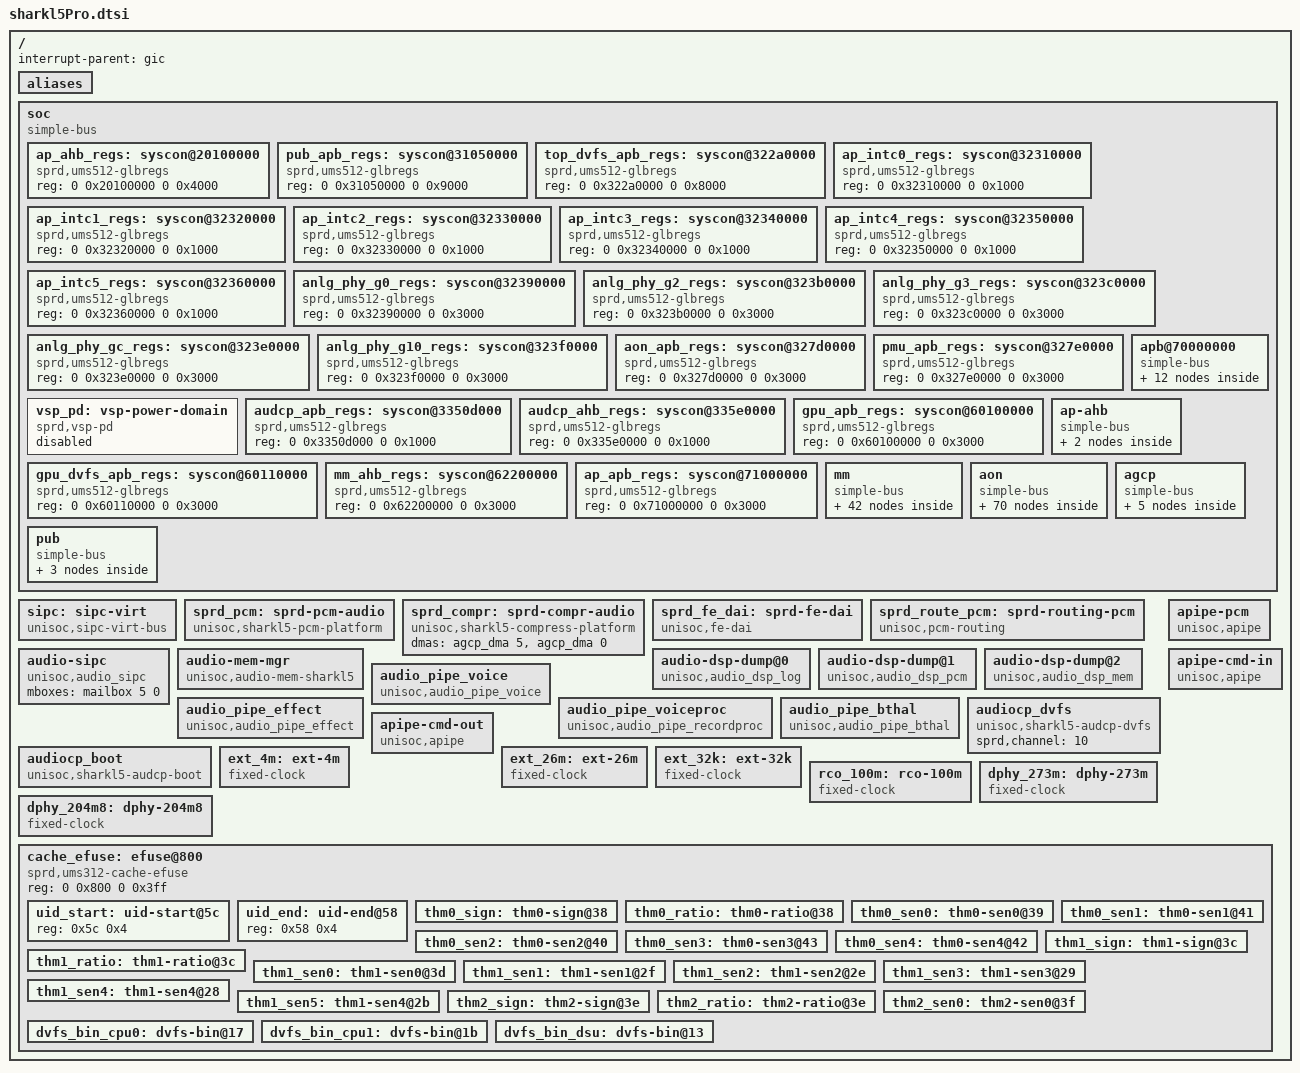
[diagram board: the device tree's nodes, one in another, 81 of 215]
// SPDX-License-Identifier: GPL-2.0-only
/*
 * Unisoc Sharkl5Pro platform DTS file
 *
 * Copyright (C) 2020, Unisoc Inc.
 */

#include <dt-bindings/soc/sprd,sharkl5pro-regs.h>
#include <dt-bindings/soc/sprd,sharkl5pro-mask.h>
#include <dt-bindings/clock/sprd,ums512-clk.h>
#include <dt-bindings/debug/busmonitor/busmonitor.h>
#include <dt-bindings/debug/dmc_mpu/sharkl5pro_dmc_mpu.h>
#include "ums512-qos.dtsi"

/ {
	interrupt-parent = <&gic>;
	#address-cells = <2>;
	#size-cells = <2>;

	aliases {
		i2c0 = &i2c0;
		i2c1 = &i2c1;
		i2c2 = &i2c2;
		i2c3 = &i2c3;
		i2c4 = &i2c4;
		i2c5 = &aon_i2c0;
		spi0 = &spi0;
		spi1 = &spi1;
		spi2 = &spi2;
		spi3 = &spi3;
		spi4 = &adi_bus;
	};

	soc: soc {
		compatible = "simple-bus";
		#address-cells = <2>;
		#size-cells = <2>;
		ranges;

		ap_ahb_regs: syscon@20100000 {
			compatible = "sprd,ums512-glbregs", "syscon";
			reg = <0 0x20100000 0 0x4000>;
		};

		pub_apb_regs: syscon@31050000 {
			compatible = "sprd,ums512-glbregs", "syscon";
			reg = <0 0x31050000 0 0x9000>;
		};

		top_dvfs_apb_regs: syscon@322a0000 {
			compatible = "sprd,ums512-glbregs", "syscon";
			reg = <0 0x322a0000 0 0x8000>;
		};

		ap_intc0_regs: syscon@32310000 {
			compatible = "sprd,ums512-glbregs", "syscon";
			reg = <0 0x32310000 0 0x1000>;
		};

		ap_intc1_regs: syscon@32320000 {
			compatible = "sprd,ums512-glbregs", "syscon";
			reg = <0 0x32320000 0 0x1000>;
		};

		ap_intc2_regs: syscon@32330000 {
			compatible = "sprd,ums512-glbregs", "syscon";
			reg = <0 0x32330000 0 0x1000>;
		};

		ap_intc3_regs: syscon@32340000 {
			compatible = "sprd,ums512-glbregs", "syscon";
			reg = <0 0x32340000 0 0x1000>;
		};

		ap_intc4_regs: syscon@32350000 {
			compatible = "sprd,ums512-glbregs", "syscon";
			reg = <0 0x32350000 0 0x1000>;
		};

		ap_intc5_regs: syscon@32360000 {
			compatible = "sprd,ums512-glbregs", "syscon";
			reg = <0 0x32360000 0 0x1000>;
		};

		anlg_phy_g0_regs: syscon@32390000 {
			compatible = "sprd,ums512-glbregs", "syscon";
			reg = <0 0x32390000 0 0x3000>;
		};

		anlg_phy_g2_regs: syscon@323b0000 {
			compatible = "sprd,ums512-glbregs", "syscon";
			reg = <0 0x323b0000 0 0x3000>;
		};

		anlg_phy_g3_regs: syscon@323c0000 {
			compatible = "sprd,ums512-glbregs", "syscon";
			reg = <0 0x323c0000 0 0x3000>;
		};

		anlg_phy_gc_regs: syscon@323e0000 {
			compatible = "sprd,ums512-glbregs", "syscon";
			reg = <0 0x323e0000 0 0x3000>;
		};

		anlg_phy_g10_regs: syscon@323f0000 {
			compatible = "sprd,ums512-glbregs", "syscon";
			reg = <0 0x323f0000 0 0x3000>;
		};

		aon_apb_regs: syscon@327d0000 {
			compatible = "sprd,ums512-glbregs", "syscon";
			reg = <0 0x327d0000 0 0x3000>;
		};

		pmu_apb_regs: syscon@327e0000 {
			compatible = "sprd,ums512-glbregs", "syscon";
			reg = <0 0x327e0000 0 0x3000>;
		};

		vsp_pd: vsp-power-domain {
			compatible = "sprd,vsp-pd";
			pmu-vsp-force-shutdown-syscon = <&pmu_apb_regs
				REG_PMU_APB_RF_PD_AP_VSP_CFG
				MASK_PMU_APB_RF_PD_AP_VSP_FORCE_SHUTDOWN>;
			pmu-vsp-auto-shutdown-syscon = <&pmu_apb_regs
				REG_PMU_APB_RF_PD_AP_VSP_CFG
				MASK_PMU_APB_RF_PD_AP_VSP_AUTO_SHUTDOWN_EN>;
			pmu-pwr-status-syscon = <&pmu_apb_regs
				REG_PMU_APB_RF_PWR_STATUS0_DBG
				MASK_PMU_APB_RF_PD_AP_VSP_STATE>;
			#power-domain-cells = <0>;
			status = "disabled";
		};

		audcp_apb_regs: syscon@3350d000 {
			compatible = "sprd,ums512-glbregs", "syscon";
			reg = <0 0x3350d000 0 0x1000>;
		};

		audcp_ahb_regs: syscon@335e0000 {
			compatible = "sprd,ums512-glbregs", "syscon";
			reg = <0 0x335e0000 0 0x1000>;
		};

		gpu_apb_regs: syscon@60100000 {
			compatible = "sprd,ums512-glbregs", "syscon";
			reg = <0 0x60100000 0 0x3000>;
		};

		gpu_dvfs_apb_regs: syscon@60110000 {
			compatible = "sprd,ums512-glbregs", "syscon";
			reg = <0 0x60110000 0 0x3000>;
		};

		mm_ahb_regs: syscon@62200000 {
			compatible = "sprd,ums512-glbregs", "syscon";
			reg = <0 0x62200000 0 0x3000>;
		};

		apb@70000000 {
			compatible = "simple-bus";
			#address-cells = <1>;
			#size-cells = <1>;
			ranges = <0 0x0 0x70000000 0x10000000>;

			uart0: serial@0 {
				compatible = "sprd,ums512-uart",
					     "sprd,sc9836-uart";
				reg = <0x0 0x100>;
				interrupts = <GIC_SPI 2 IRQ_TYPE_LEVEL_HIGH>;
				source-base = <0x20200028>;
				clock-frequency = <0>;
				uart-eb-syscon = <&ap_apb_regs
						REG_AP_APB_RF_APB_EB
						MASK_AP_APB_RF_UART0_EB>;
				clocks = <&ext_26m>;
				status = "disabled";
			};

			uart1: serial@100000 {
				compatible = "sprd,ums512-uart",
					     "sprd,sc9836-uart";
				reg = <0x100000 0x100>;
				interrupts = <GIC_SPI 3 IRQ_TYPE_LEVEL_HIGH>;
				source-base = <0x2020002c>;
				clock-frequency = <0>;
				uart-eb-syscon = <&ap_apb_regs
						REG_AP_APB_RF_APB_EB
						MASK_AP_APB_RF_UART1_EB>;
				clocks = <&ext_26m>;
				status = "disabled";
			};

			i2c0: i2c@300000 {
				compatible = "sprd,ums512-i2c", "sprd,sc9860-i2c";
				reg = <0x300000 0x100>;
				interrupts = <GIC_SPI 11 IRQ_TYPE_LEVEL_HIGH>;
				clock-frequency = <400000>;
				#address-cells = <1>;
				#size-cells = <0>;
				status = "disabled";
			};

			i2c1: i2c@400000 {
				compatible = "sprd,ums512-i2c", "sprd,sc9860-i2c";
				reg = <0x400000 0x100>;
				interrupts = <GIC_SPI 12 IRQ_TYPE_LEVEL_HIGH>;
				clock-frequency = <400000>;
				#address-cells = <1>;
				#size-cells = <0>;
				status = "disabled";
			};

			i2c2: i2c@500000 {
				compatible = "sprd,ums512-i2c", "sprd,sc9860-i2c";
				reg = <0x500000 0x100>;
				interrupts = <GIC_SPI 13 IRQ_TYPE_LEVEL_HIGH>;
				clock-frequency = <400000>;
				#address-cells = <1>;
				#size-cells = <0>;
				status = "disabled";
			};

			i2c3: i2c@600000 {
				compatible = "sprd,ums512-i2c", "sprd,sc9860-i2c";
				reg = <0x600000 0x100>;
				interrupts = <GIC_SPI 14 IRQ_TYPE_LEVEL_HIGH>;
				clock-frequency = <400000>;
				#address-cells = <1>;
				#size-cells = <0>;
				status = "disabled";
			};

			i2c4: i2c@700000 {
				compatible = "sprd,ums512-i2c", "sprd,sc9860-i2c";
				reg = <0x700000 0x100>;
				interrupts = <GIC_SPI 15 IRQ_TYPE_LEVEL_HIGH>;
				clock-frequency = <400000>;
				#address-cells = <1>;
				#size-cells = <0>;
				status = "disabled";
			};

			spi0: spi@800000{
				compatible = "sprd,ums512-spi",
					     "sprd,sc9860-spi";
				reg = <0x800000 0x1000>;
				interrupts = <GIC_SPI 5 IRQ_TYPE_LEVEL_HIGH>;
				#address-cells = <1>;
				#size-cells = <0>;
				status = "disabled";
			};

			spi1: spi@900000{
				compatible = "sprd,ums512-spi",
					     "sprd,sc9860-spi";
				reg = <0x900000 0x1000>;
				interrupts = <GIC_SPI 6 IRQ_TYPE_LEVEL_HIGH>;
				#address-cells = <1>;
				#size-cells = <0>;
				status = "disabled";
			};

			spi2: spi@a00000{
				compatible = "sprd,ums512-spi",
					     "sprd,sc9860-spi";
				reg = <0xa00000 0x1000>;
				interrupts = <GIC_SPI 7 IRQ_TYPE_LEVEL_HIGH>;
				#address-cells = <1>;
				#size-cells = <0>;
				status = "disabled";
			};

			spi3: spi@b00000{
				compatible = "sprd,ums512-spi",
					     "sprd,sc9860-spi";
				reg = <0xb00000 0x1000>;
				interrupts = <GIC_SPI 8 IRQ_TYPE_LEVEL_HIGH>;
				#address-cells = <1>;
				#size-cells = <0>;
				status = "disabled";
			};

			apsys_dvfs: apsys-dvfs@1700000 {
				compatible = "sprd,hwdvfs-apsys-sharkl5pro";
				reg = <0x1700000 0x15c>;

				sprd,ap-dvfs-up-window = <0x40>;
				sprd,ap-dvfs-down-window = <0x80>;
			};
		};

		ap_apb_regs: syscon@71000000 {
			compatible = "sprd,ums512-glbregs", "syscon";
			reg = <0 0x71000000 0 0x3000>;
		};

		ap-ahb {
			compatible = "simple-bus";
			#address-cells = <2>;
			#size-cells = <2>;
			ranges;

			ap_dma: dma-controller@20000000 {
				compatible = "sprd,sharkl5pro-dma", "sprd,sc9860-dma";
				reg = <0 0x20000000 0 0x4000>;
				interrupts = <GIC_SPI 24 IRQ_TYPE_LEVEL_HIGH>;
				#dma-cells = <1>;
				#dma-channels = <28>;
				clock-names = "enable";
				clocks = <&apahb_gate CLK_DMA_PUB_EB>;
			};

			vdsp: vdsp@20900000 {
				compatible = "sprd,sharkl5pro-vdsp";
				/* IPI */
				reg = <0x0 0x20900000 0x0 0x10000>;
				sprd,syscon-ap-ahb = <&ap_ahb_regs>;
				sprd,syscon-pmu = <&pmu_apb_regs>;
				clock-names = "vdsp_clk_set","vdsp_clk_512";
				clocks = <&ap_clk CLK_VDSP>,
					     <&pll2  CLK_TWPLL_512M>;
				iommu_names = "unisoc,iommuvau-epp-l5p",
							"unisoc,iommuvau-edp-l5p",
							"unisoc,iommuvau-idma-l5p",
							"unisoc,iommuvau-vdma-l5p";
				queue-priority = <7 8 9>;
				/* offset, bit#, IRQ# */
				device-irq = <0 4 1>;
				device-irq-host-offset = <0>;
				device-irq-mode = <1>;
				/* offset, bit# */
				host-irq = <0x8 0>;
				host-irq-mode = <1>;
				interrupts = <GIC_SPI 169 IRQ_TYPE_LEVEL_HIGH>;
				firmware-name = "vdsp_firmware.bin";
				/* vdsp-qos = <&vdsp_qos>; */
				status = "disabled";
			};
		};

		mm {
			compatible = "simple-bus";
			#address-cells = <2>;
			#size-cells = <2>;
			ranges;

			gpu: gpu@60000000 {
				compatible = "sprd,mali-gondul";
				reg = <0x0 0x60000000 0x0 0x100000>;
				gpu-supply = <&vddgpu>;
				system-coherency = <31>;
				top_force_shutdown = <&pmu_apb_regs
					REG_PMU_APB_RF_PD_GPU_TOP_CFG0
					MASK_PMU_APB_RF_PD_GPU_TOP_FORCE_SHUTDOWN>;
				mem_repaired_flag = <&aon_apb_regs
					REG_AON_APB_RF_BOND_OPT0
					MASK_AON_APB_RF_BOND_OPTION0>;
				gpu_qos_sel = <&gpu_apb_regs
					REG_GPU_APB_RF_GPU_NIC400_QOS
					MASK_GPU_APB_RF_GPU_QOS_SEL>;
				gpu_qos = <&gpu_apb_regs
					REG_GPU_APB_RF_GPU_NIC400_QOS
					(MASK_GPU_APB_RF_AWQOS_THRESHOLD_GPU |
					MASK_GPU_APB_RF_ARQOS_THRESHOLD_GPU |
					MASK_GPU_APB_RF_AWQOS_GPU |
					MASK_GPU_APB_RF_ARQOS_GPU)>;
				dvfs_index_cfg = <&gpu_dvfs_apb_regs
					REG_GPU_DVFS_APB_RF_GPU_DVFS_INDEX_CFG
					MASK_GPU_DVFS_APB_RF_GPU_DVFS_INDEX>;
				sw_dvfs_ctrl = <&gpu_dvfs_apb_regs
					REG_GPU_DVFS_APB_RF_GPU_SW_DVFS_CTRL
					(MASK_GPU_DVFS_APB_RF_GPU_DVFS_ACK |
					MASK_GPU_DVFS_APB_RF_GPU_DVFS_VOLTAGE_SW |
					MASK_GPU_DVFS_APB_RF_GPU_DVFS_REQ_SW)>;
				freq_upd_cfg = <&gpu_dvfs_apb_regs
					REG_GPU_DVFS_APB_RF_GPU_FREQ_UPD_TYPE_CFG
					(MASK_GPU_DVFS_APB_RF_GPU_CORE_FREQ_UPD_HDSK_EN |
					 MASK_GPU_DVFS_APB_RF_GPU_CORE_FREQ_UPD_DELAY_EN)>;
				core_index0_map = <&gpu_dvfs_apb_regs
					REG_GPU_DVFS_APB_RF_GPU_CORE_INDEX0_MAP
					MASK_GPU_DVFS_APB_RF_GPU_CORE_VOL_INDEX0>;
				core_index1_map = <&gpu_dvfs_apb_regs
					REG_GPU_DVFS_APB_RF_GPU_CORE_INDEX1_MAP
					MASK_GPU_DVFS_APB_RF_GPU_CORE_VOL_INDEX1>;
				core_index2_map = <&gpu_dvfs_apb_regs
					REG_GPU_DVFS_APB_RF_GPU_CORE_INDEX2_MAP
					MASK_GPU_DVFS_APB_RF_GPU_CORE_VOL_INDEX2>;
				core_index3_map = <&gpu_dvfs_apb_regs
					REG_GPU_DVFS_APB_RF_GPU_CORE_INDEX3_MAP
					MASK_GPU_DVFS_APB_RF_GPU_CORE_VOL_INDEX3>;
				core_index4_map = <&gpu_dvfs_apb_regs
					REG_GPU_DVFS_APB_RF_GPU_CORE_INDEX4_MAP
					MASK_GPU_DVFS_APB_RF_GPU_CORE_VOL_INDEX4>;
				core_index5_map = <&gpu_dvfs_apb_regs
					REG_GPU_DVFS_APB_RF_GPU_CORE_INDEX5_MAP
					MASK_GPU_DVFS_APB_RF_GPU_CORE_VOL_INDEX5>;
				core_index6_map = <&gpu_dvfs_apb_regs
					REG_GPU_DVFS_APB_RF_GPU_CORE_INDEX6_MAP
					MASK_GPU_DVFS_APB_RF_GPU_CORE_VOL_INDEX6>;
				core_index7_map = <&gpu_dvfs_apb_regs
					REG_GPU_DVFS_APB_RF_GPU_CORE_INDEX7_MAP
					MASK_GPU_DVFS_APB_RF_GPU_CORE_VOL_INDEX7>;

				interrupts = <GIC_SPI 60 IRQ_TYPE_LEVEL_HIGH>,
					<GIC_SPI 60 IRQ_TYPE_LEVEL_HIGH>,
					<GIC_SPI 60 IRQ_TYPE_LEVEL_HIGH>;
				interrupt-names = "JOB",
					"MMU",
					"GPU";

				/*nvmem-cells = <&gpu_bin>;
				nvmem-cell-names = "gpu_bin";*/

				operating-points = <
					/* kHz    uV */
					384000    700000
					512000    750000
					614400    750000
					768000    800000
					850000    800000
					>;

				sprd,dvfs-lists = <
					/* kHz   uV      idx div */
					384000  700000    4    1
					512000  750000    5    1
					614400  750000    6    1
					768000  800000    7    1
					850000  800000    8    1
					>;

				sprd,dvfs-default = <0>;
				/*sprd,qos = <&gpu_qos>;*/
				sprd,dvfs-scene-extreme = <3>;
				sprd,dvfs-scene-high = <2>;
				sprd,dvfs-scene-medium = <1>;
				sprd,dvfs-scene-low = <0>;
				sprd,dvfs-range-max = <4>;
				sprd,dvfs-range-min = <0>;
			};

			mm_domain: power-domain@327e0024 {
				compatible = "sprd,sharkl5pro-camsys-domain";
				force-shutdown = <&pmu_apb_regs
					REG_PMU_APB_RF_PD_MM_TOP_CFG
					MASK_PMU_APB_RF_PD_MM_TOP_FORCE_SHUTDOWN>;
				shutdown-en = <&pmu_apb_regs
					REG_PMU_APB_RF_PD_MM_TOP_CFG
					MASK_PMU_APB_RF_PD_MM_TOP_AUTO_SHUTDOWN_EN>;
				power-state = <&pmu_apb_regs
					REG_PMU_APB_RF_PWR_STATUS3_DBG
					MASK_PMU_APB_RF_PD_MM_TOP_STATE>;
				qos-ar = <&mm_ahb_regs
					REG_MM_AHB_RF_MM_QOS
					MASK_MM_AHB_RF_AR_QOS_THRESHOLD_MM>;
				qos-aw = <&mm_ahb_regs
					REG_MM_AHB_RF_MM_QOS
					MASK_MM_AHB_RF_AW_QOS_THRESHOLD_MM>;
				aon-apb-mm-eb = <&aon_apb_regs
					REG_AON_APB_RF_APB_EB0
					MASK_AON_APB_RF_MM_EB>;
				clock-names = "clk_mm_eb",
					"clk_mm_ahb_eb",
					"clk_mm_ahb",
					"clk_mm_ahb_parent",
					"clk_mm_mtx",
					"clk_mm_mtx_parent",
					"clk_isppll";
				clocks = <&aonapb_gate CLK_MM_EB>,
					<&mm_gate CLK_MM_CKG_EB>,
					<&mm_clk CLK_MM_AHB>,
					<&pll2 CLK_TWPLL_153M6>,
					<&mm_clk CLK_MM_MTX>,
					<&pll2 CLK_TWPLL_512M>,
					<&pll2 CLK_ISPPLL_468M>;
				mm_qos_threshold = <&mm_qos_threshold>;
				#power-domain-cells = <0>;
				status = "disabled";
			};

			mipi_csi_phy0: mipi-csi-phy0 {
				compatible = "sprd,mipi-csi-phy";
				sprd,phyid = <0>;
				sprd,phyname = "4lane";
				status = "disabled";
			};

			mipi_csi_phy1: mipi-csi-phy1 {
				compatible = "sprd,mipi-csi-phy";
				sprd,phyid = <1>;
				sprd,phyname = "2p2";
				status = "disabled";
			};

			mipi_csi_phy1_m: mipi-csi-phy1-m {
				compatible = "sprd,mipi-csi-phy";
				sprd,phyid = <3>;
				sprd,phyname = "2p2_m";
				status = "disabled";
			};

			mipi_csi_phy1_s: mipi-csi-phy1-s {
				compatible = "sprd,mipi-csi-phy";
				sprd,phyid = <4>;
				sprd,phyname = "2p2_s";
				status = "disabled";
			};

			mipi_csi_phy2: mipi-csi-phy2 {
				compatible = "sprd,mipi-csi-phy";
				sprd,phyid = <2>;
				sprd,phyname = "2lane";
				status = "disabled";
			};

			csi0: csi00@62300000 {
				compatible = "sprd,csi-controller";
				reg = <0 0x62300000 0 0x1000>;
				interrupts = <GIC_SPI 45 IRQ_TYPE_LEVEL_HIGH>,
					<GIC_SPI 46 IRQ_TYPE_LEVEL_HIGH>,
					<GIC_SPI 47 IRQ_TYPE_LEVEL_HIGH>,
					<GIC_SPI 48 IRQ_TYPE_LEVEL_HIGH>;
				clock-names = "clk_mipi_csi_gate_eb",
					"clk_csi_eb",
					"mipi_csi_src_eb";
				clocks = <&mm_gate CLK_MM_MIPI_CSI0_EB>,
					<&mm_gate CLK_MM_CSI0_EB>,
					<&mm_clk CLK_MIPI_CSI0>;
				sprd,aon-apb-syscon = <&aon_apb_regs>;
				sprd,cam-ahb-syscon = <&mm_ahb_regs>;
				sprd,anlg_phy_g10_controller =
					<&anlg_phy_g10_regs>;
				sprd,csi-id = <0>;
				sprd,dcam-id = <0>;
				sprd,ip-version = <0x200>;
				status = "disabled";
			};

			csi1: csi01@62400000 {
				compatible = "sprd,csi-controller";
				reg = <0 0x62400000 0 0x1000>;
				interrupts = <GIC_SPI 49 IRQ_TYPE_LEVEL_HIGH>,
					<GIC_SPI 50 IRQ_TYPE_LEVEL_HIGH>,
					<GIC_SPI 51 IRQ_TYPE_LEVEL_HIGH>,
					<GIC_SPI 52 IRQ_TYPE_LEVEL_HIGH>;
				clock-names = "clk_mipi_csi_gate_eb",
					"clk_csi_eb",
					"mipi_csi_src_eb";
				clocks = <&mm_gate CLK_MM_MIPI_CSI1_EB>,
					<&mm_gate CLK_MM_CSI1_EB>,
					<&mm_clk CLK_MIPI_CSI1>;
				sprd,aon-apb-syscon = <&aon_apb_regs>;
				sprd,cam-ahb-syscon = <&mm_ahb_regs>;
				sprd,anlg_phy_g10_controller =
					<&anlg_phy_g10_regs>;
				sprd,csi-id = <1>;
				sprd,dcam-id = <1>;
				sprd,ip-version = <0x200>;
				status = "disabled";
			};

			csi2: csi02@62500000 {
				compatible = "sprd,csi-controller";
				reg = <0 0x62500000 0 0x1000>;
				interrupts = <GIC_SPI 53 IRQ_TYPE_LEVEL_HIGH>,
					<GIC_SPI 54 IRQ_TYPE_LEVEL_HIGH>,
					<GIC_SPI 55 IRQ_TYPE_LEVEL_HIGH>,
					<GIC_SPI 56 IRQ_TYPE_LEVEL_HIGH>;
				clock-names = "clk_mipi_csi_gate_eb",
					"clk_csi_eb",
					"mipi_csi_src_eb";
				clocks = <&mm_gate CLK_MM_MIPI_CSI2_EB>,
					<&mm_gate CLK_MM_CSI2_EB>,
					<&mm_clk CLK_MIPI_CSI2>;
				sprd,aon-apb-syscon = <&aon_apb_regs>;
				sprd,cam-ahb-syscon = <&mm_ahb_regs>;
				sprd,anlg_phy_g10_controller =
					<&anlg_phy_g10_regs>;
				sprd,csi-id = <2>;
				sprd,dcam-id = <2>;
				sprd,ip-version = <0x200>;
				status = "disabled";
			};

			isp: isp@62000000 {
				compatible = "sprd,isp";
				reg = <0 0x62000000 0 0x100000>;
				interrupts = <GIC_SPI 43 IRQ_TYPE_LEVEL_HIGH>,
					<GIC_SPI 44 IRQ_TYPE_LEVEL_HIGH>;
				interrupts_name = "ispch0", "ispch1";
				clock-names = "isp_eb",
					"isp_axi_eb", /* no need read, TBC */
					"isp_clk",
					"isp_clk_256m",
					"isp_clk_307m2",
					"isp_clk_384m",
					"isp_clk_468m",
					"isp_clk_512m",
					"isp_clk_parent";
				clocks = <&mm_gate CLK_MM_ISP_EB>,
					<&mm_gate CLK_ISP_AHB_EB>,
					<&mm_clk CLK_ISP>,
					<&pll2 CLK_TWPLL_256M>,
					<&pll2 CLK_TWPLL_307M2>,
					<&pll2 CLK_TWPLL_384M>,
					<&pll2 CLK_ISPPLL_468M>,
					<&pll2 CLK_TWPLL_512M>,
					<&pll2 CLK_TWPLL_512M>;
				reset = <&mm_ahb_regs
					REG_MM_AHB_RF_AHB_RST
					MASK_MM_AHB_RF_ISP_SOFT_RST>;
				isp_ahb_reset = <&mm_ahb_regs
					REG_MM_AHB_RF_AHB_RST
					MASK_MM_AHB_RF_ISP_AHB_SOFT_RST>;
				isp_vau_reset = <&mm_ahb_regs
					REG_MM_AHB_RF_AHB_RST
					MASK_MM_AHB_RF_ISP_VAU_SOFT_RST>;
				isp_enable = <&mm_ahb_regs
					REG_MM_AHB_RF_AHB_EB
					MASK_MM_AHB_RF_ISP_EB>;
				sprd,cam-ahb-syscon = <&mm_ahb_regs>;
				sprd,isp-count = <1>;
				iommus = <&iommu_isp>;
				isp_qos = <&isp_qos>;
				status = "disabled";
			};

			iommu_isp: iommu@62000000 {
				compatible = "unisoc,iommuvaul5p-isp";
				reg = <0x0 0x62000000 0x0 0xff000>,
				      <0x0 0x620ff000 0x0 0x80>;
				iova-base = <0x40000000>;
				iova-size = <0x20000000>;
				reg_name = "mmu_interrupt_reg","mmu_reg";
				status = "disabled";
				#iommu-cells = <0>;
			};

			dcam: dcam@62900000 {
				compatible = "sprd,sharkl5pro-cam";
				reg = <0 0x62900000 0 0x1000>,
					<0 0x62901000 0 0x1000>,
					<0 0x62902000 0 0x1000>,
					<0 0x62903000 0 0x1000>;
				reg-names = "dcam0_reg",
						"dcam1_reg",
						"dcam2_reg",
						"axi_ctrl_reg";
				interrupts = <GIC_SPI 57 IRQ_TYPE_LEVEL_HIGH>,
					<GIC_SPI 58 IRQ_TYPE_LEVEL_HIGH>,
					<GIC_SPI 59 IRQ_TYPE_LEVEL_HIGH>;
				interrupt-names = "dcam0",
							"dcam1",
							"dcam2";
				clock-names = "dcam_eb",
					"dcam_clk",
					"dcam_clk_192m",
					"dcam_clk_256m",
					"dcam_clk_307m2",
					"dcam_clk_384m",
					"dcam_clk_468m",
					"dcam_clk_parent",
					"dcam_axi_eb",
					"dcam_axi_clk",
					"dcam_axi_clk_256m",
					"dcam_axi_clk_307m2",
					"dcam_axi_clk_384m",
					"dcam_axi_clk_468m",
					"dcam_axi_clk_parent";
				clocks = <&mm_gate CLK_MM_DCAM_EB>,
					<&mm_clk CLK_DCAM_IF>,
					<&pll2 CLK_TWPLL_192M>,
					<&pll2 CLK_TWPLL_256M>,
					<&pll2 CLK_TWPLL_307M2>,
					<&pll2 CLK_TWPLL_384M>,
					<&pll2 CLK_ISPPLL_468M>,
					<&pll2 CLK_ISPPLL_468M>,
					<&mm_gate CLK_DCAM_AXI_EB>,
					<&mm_clk CLK_DCAM_AXI>,
					<&pll2 CLK_TWPLL_256M>,
					<&pll2 CLK_TWPLL_307M2>,
					<&pll2 CLK_TWPLL_384M>,
					<&pll2 CLK_ISPPLL_468M>,
					<&pll2 CLK_ISPPLL_468M>;
				dcam_all_reset = <&mm_ahb_regs
					REG_MM_AHB_RF_AHB_RST
					MASK_MM_AHB_RF_DCAM_ALL_SOFT_RST>;
				dcam0_reset	= <&mm_ahb_regs
					REG_MM_AHB_RF_AHB_RST
					MASK_MM_AHB_RF_DCAM0_SOFT_RST>;
				dcam1_reset	= <&mm_ahb_regs
					REG_MM_AHB_RF_AHB_RST
					MASK_MM_AHB_RF_DCAM1_SOFT_RST>;
				dcam2_reset	= <&mm_ahb_regs
					REG_MM_AHB_RF_AHB_RST
					MASK_MM_AHB_RF_DCAM2_SOFT_RST>;
				sprd,cam-ahb-syscon = <&mm_ahb_regs>;
				sprd,isp = <&isp>;
				sprd,dcam-count = <3>;
				sprd,dcam-superzoom = <2>;
				sprd,project-id = <3>;
				iommus = <&iommu_dcam>;
				dcam_qos = <&dcam_qos>;
				power-domains = <&mm_domain>;
				status = "disabled";
			};

			iommu_dcam: iommu@62900000 {
				compatible = "unisoc,iommuvaul5p-dcam";
				reg = <0x0 0x62900000 0x0 0xf000>,
				      <0x0 0x6290f000 0x0 0x80>;
				iova-base = <0x40000000>;
				iova-size = <0x40000000>;
				reg_name = "mmu_interrupt_reg","mmu_reg";
				status = "disabled";
				#iommu-cells = <0>;
			};

			cpp: cpp@62800000 {
				compatible = "sprd,cpp";
				reg = <0 0x62800000 0 0x1000>;
				interrupts = <GIC_SPI 41 IRQ_TYPE_LEVEL_HIGH>;
				clock-names = "cpp_eb",
					"cpp_axi_eb", /* no need read, TBC */
					"cpp_clk",
					"cpp_clk_parent";
				clocks = <&mm_gate CLK_MM_CPP_EB>,
					<&mm_gate CLK_MM_ISP_EB>,
					<&mm_clk CLK_CPP>,
					<&pll2 CLK_TWPLL_384M>;
				sprd,cam-ahb-syscon = <&mm_ahb_regs>;
				iommus = <&iommu_cpp>;
				cpp_qos = <&cpp_qos>;
				power-domains = <&mm_domain>;
				status = "disabled";
			};

			iommu_cpp: iommu@62800000 {
				compatible = "unisoc,iommuvaul5p-cpp";
				reg = <0x0 0x62800000 0x0 0x200>,
				      <0x0 0x62800200 0x0 0x80>;
				iova-base = <0x40000000>;
				iova-size = <0x20000000>;
				reg_name = "mmu_interrupt_reg","mmu_reg";
				status = "disabled";
				#iommu-cells = <0>;
			};

			iommu_fd: iommu@62a00000 {
				compatible = "unisoc,iommuvaul5p-fd";
				reg = <0 0x62a00000 0 0x200>,
				      <0 0x62a00110 0 0x80>;
				iova-base = <0x10000000>;
				iova-size = <0x10000000>;
				reg_name = "mmu_interrupt_reg","mmu_reg";
				status = "disabled";
				#iommu-cells = <0>;
			};

			jpg: jpg-codec@62700000 {
				compatible = "sprd,sharkl5pro-jpg";
				reg = <0 0x62700000 0 0xc000>;
				interrupts = <GIC_SPI 42 IRQ_TYPE_LEVEL_HIGH>;
				reset-syscon = <&mm_ahb_regs
					REG_MM_AHB_RF_AHB_RST
					MASK_MM_AHB_RF_JPG_SOFT_RST>;
				aon-apb-eb-syscon = <&aon_apb_regs
					REG_AON_APB_RF_APB_EB0
					MASK_AON_APB_RF_MM_EB>;
				iommus = <&iommu_jpg>;
				power-domains = <&mm_domain>;
				/*sprd,qos = <&jpg_qos>;*/
				status = "disabled";
			};

			iommu_jpg: iommu@62700300 {
				compatible = "unisoc,iommuvaul5p-jpg";
				reg = <0x0 0x62700300 0x0 0x80>,
					<0x0 0x62700300 0x0 0x80>;
				iova-base = <0x60000000>;
				iova-size = <0x10000000>;
				reg_name = "mmu_reg";
				status = "disabled";
				#iommu-cells = <0>;
			};

			dpu: dpu@20300000 {
				compatible = "sprd,sharkl5pro-dpu";
				reg = <0x0 0x20300000 0x0 0x1000>;
				reset-syscon = <&ap_ahb_regs 0x0004 0x2>;
				interrupts = <GIC_SPI 27 IRQ_TYPE_LEVEL_HIGH>;
				status = "disabled";
				iommus = <&iommu_dispc>;
				sprd,qos = <&dpu_qos>;

				dpu_port: port {
					dpu_out: endpoint {
						remote-endpoint = <&dsi_in>;
					};
				};
			};

			gsp_core0: gsp@20300000 {
				compatible = "sprd,gsp-core";
				reg = <0 0x20300000 0 0x2000>;
				core-id = <0>;
				kcfg-num = <16>;
				interrupts = <GIC_SPI 26 IRQ_TYPE_LEVEL_HIGH>;
				iommus = <&iommu_dispc>;
			};

			iommu_dispc: iommu@20300000 {
				compatible = "unisoc,iommuvaul5p-dispc";
				reg = <0x0 0x20300000 0x0 0x800>,
				      <0x0 0x20300800 0x0 0x80>;
				iova-base = <0x30000000>;
				iova-size = <0x10000000>;
				reg_name = "mmu_interrupt_reg","mmu_reg";
				status = "disabled";
				#iommu-cells = <0>;
			};

			dsi: dsi@20400000 {
				compatible = "sprd,sharkl5pro-dsi-host";
				reg = <0x0 0x20400000 0x0 0x1000>;
				reset-syscon = <&ap_ahb_regs 0x0004 0x1>;
				interrupts = <GIC_SPI 30 IRQ_TYPE_LEVEL_HIGH>,
					<GIC_SPI 31 IRQ_TYPE_LEVEL_HIGH>;
				status = "disabled";

				ports {
					#address-cells = <1>;
					#size-cells = <0>;

					port@0 {
						reg = <0>;
						dsi_out: endpoint {
							remote-endpoint = <&dphy_in>;
						};
					};

					port@1 {
						reg = <1>;
						dsi_in: endpoint {
							remote-endpoint = <&dpu_out>;
						};
					};
				};
			};

			dphy: dphy {
				compatible = "sprd,sharkl5pro-dsi-phy";
				#address-cells = <1>;
				#size-cells = <0>;
				reg = <0x0 0x20400000 0x0 0x1000>;
				enable-syscon = <&ap_ahb_regs 0x0040 (0x2 | 0x1)>;
				power-syscon = <&ap_apb_regs 0x035c 0x8>;
				status = "disabled";

				/* output port */
				ports {
					#address-cells = <1>;
					#size-cells = <0>;

					port@0 {
						reg = <0>;
						dphy_out: endpoint {
							remote-endpoint = <&panel_in>;
						};
					};

					/* input port*/
					port@1 {
						reg = <1>;
						dphy_in: endpoint {
							remote-endpoint = <&dsi_out>;
						};
					};
				};
			};

			vsp: video-codec@20500000 {
				compatible = "sprd,sharkl5pro-vsp";
				reg = <0 0x20500000 0 0xc000>;
				interrupts = <GIC_SPI 34 IRQ_TYPE_LEVEL_HIGH>;
				reset-syscon = <&ap_ahb_regs
					REG_AP_AHB_RF_AHB_RST
					(MASK_AP_AHB_RF_VSP_SOFT_RST |
					MASK_AP_AHB_RF_VSP_GLOBAL_SOFT_RST)>;
				vsp-domain-eb-syscon = <&aon_apb_regs
					REG_AON_APB_RF_APB_EB1
					MASK_AON_APB_RF_AP_SYST_EB>;
				iommus = <&iommu_vsp>;
				power-domains = <&vsp_pd>;
				status = "disabled";
			};

			iommu_vsp: iommu@20500000 {
				compatible = "unisoc,iommuvaul5p-vsp";
				reg = <0x0 0x20500000 0x0 0x80>,
				      <0x0 0x20500000 0x0 0x80>;
				iova-base = <0x20000000>;
				iova-size = <0x10000000>;
				reg_name = "mmu_interrupt_reg","mmu_reg";
				status = "disabled";
				#iommu-cells = <0>;
			};

			iommu_vdsp_msti: iommu@20600000 {
				compatible = "unisoc,iommuvau-epp-l5p";
				reg = <0 0x20600000 0 0x400>,
				      <0 0x20600000 0 0x400>;
				reg_name = "mmu_interrupt_reg","mmu_reg";
				iova-base = <0x80000000>;
				iova-size = <0x20000000>;
				status = "disabled";
				#iommu-cells = <0>;
			};

			iommu_vdsp_mstd: iommu@20700000 {
				compatible = "unisoc,iommuvau-edp-l5p";
				reg = <0 0x20700000 0 0x400>,
				      <0 0x20700000 0 0x400>;
				reg_name = "mmu_interrupt_reg","mmu_reg";
				iova-base = <0x80000000>;
				iova-size = <0x20000000>;
				status = "disabled";
				#iommu-cells = <0>;
			};

			iommu_vdsp_idma: iommu@20800000 {
				compatible = "unisoc,iommuvau-idma-l5p";
				reg = <0 0x20800000 0 0x400>,
				      <0 0x20800000 0 0x400>;
				reg_name = "mmu_interrupt_reg","mmu_reg";
				iova-base = <0x80000000>;
				iova-size = <0x20000000>;
				status = "disabled";
				#iommu-cells = <0>;
			};

			iommu_vdsp_vdma: iommu@20a00000 {
				compatible = "unisoc,iommuvau-vdma-l5p";
				reg = <0 0x20a00000 0 0x400>,
				      <0 0x20a00000 0 0x400>;
				reg_name = "mmu_interrupt_reg","mmu_reg";
				iova-base = <0x80000000>;
				iova-size = <0x20000000>;
				status = "disabled";
				#iommu-cells = <0>;
			};
		};

		aon {
			compatible = "simple-bus";
			#address-cells = <2>;
			#size-cells = <2>;
			ranges;

			eic_debounce: gpio@32000000 {
				compatible = "sprd,sharkl5pro-eic-debounce", "sprd,sc9860-eic-debounce";
				reg = <0 0x32020000 0 0x80>,
				      <0 0x32030000 0 0x80>,
				      <0 0x32230000 0 0x80>,
				      <0 0x32270000 0 0x80>;
				gpio-controller;
				#gpio-cells = <2>;
				interrupt-controller;
				#interrupt-cells = <2>;
				interrupts = <GIC_SPI 72 IRQ_TYPE_LEVEL_HIGH>;
			};

			eic_latch: gpio@32000080 {
				compatible = "sprd,sharkl5pro-eic-latch", "sprd,sc9860-eic-latch";
				reg = <0 0x32020080 0 0x20>,
				      <0 0x32030080 0 0x20>,
				      <0 0x32230080 0 0x20>,
				      <0 0x32270080 0 0x20>;
				gpio-controller;
				#gpio-cells = <2>;
				interrupt-controller;
				#interrupt-cells = <2>;
				interrupts = <GIC_SPI 72 IRQ_TYPE_LEVEL_HIGH>;
			};

			eic_async: gpio@320000a0 {
				compatible = "sprd,sharkl5pro-eic-async", "sprd,sc9860-eic-async";
				reg = <0 0x320200a0 0 0x20>,
				      <0 0x320300a0 0 0x20>,
				      <0 0x322300a0 0 0x20>,
				      <0 0x322700a0 0 0x20>;
				gpio-controller;
				#gpio-cells = <2>;
				interrupt-controller;
				#interrupt-cells = <2>;
				interrupts = <GIC_SPI 72 IRQ_TYPE_LEVEL_HIGH>;
			};

			eic_sync: gpio@320000c0 {
				compatible = "sprd,sharkl5pro-eic-sync", "sprd,sc9860-eic-sync";
				reg = <0 0x320200c0 0 0x20>,
				      <0 0x320300c0 0 0x20>,
				      <0 0x322300c0 0 0x20>,
				      <0 0x322700c0 0 0x20>;
				gpio-controller;
				#gpio-cells = <2>;
				interrupt-controller;
				#interrupt-cells = <2>;
				interrupts = <GIC_SPI 72 IRQ_TYPE_LEVEL_HIGH>;
			};

			timer@32040000 {
				compatible = "sprd,sysfrt-timer";
				reg = <0 0x32040000 0 0x10>;
			};

			timer@32050000 {
				compatible = "sprd,sharkl5Pro-timer",
						"sprd,sc9860-timer";
				reg = <0 0x32050000 0 0x20>;
				interrupts = <GIC_SPI 71 IRQ_TYPE_LEVEL_HIGH>;
				clocks = <&ext_32k>;
			};

			timer@32050020 {
				compatible = "sprd,sharkl5Pro-suspend-timer",
						"sprd,sc9860-suspend-timer";
				reg = <0 0x32050020 0 0x20>;
				clocks = <&ext_32k>;
			};

			aon_i2c0: i2c@32060000 {
				compatible = "sprd,sharkl5pro-hw-i2c";
				reg = <0 0x32060000 0 0x1000>;
				interrupts = <GIC_SPI 68 IRQ_TYPE_LEVEL_HIGH>;
				clock-names = "source", "enable", "i2c",
						"clk_hw_i2c";
				clock-frequency = <400000>;
				#address-cells = <1>;
				#size-cells = <0>;
				status = "disabled";
			};

			ap_gpio: gpio@32070000 {
				compatible = "sprd,sharkl5Pro-gpio", "sprd,sc9860-gpio";
				reg = <0 0x32070000 0 0x10000>;
				gpio-controller;
				#gpio-cells = <2>;
				interrupt-controller;
				#interrupt-cells = <2>;
				interrupts = <GIC_SPI 61 IRQ_TYPE_LEVEL_HIGH>;
			};

			mailbox: mailbox@320a0000 {
				compatible = "unisoc,mailbox";
				reg = <0 0x320a0000 0 0x8000>,
				      <0 0x320a8000 0 0x8000>;
				reg-names = "inbox", "outbox";
				sprd,mailbox_clk = <&aon_apb_regs 0x4 0x4>;
				interrupts = <GIC_SPI 82 IRQ_TYPE_LEVEL_HIGH>,
					     <GIC_SPI 83 IRQ_TYPE_LEVEL_HIGH>,
					     <GIC_SPI 84 IRQ_TYPE_LEVEL_HIGH>;
				interrupt-names = "inbox", "outbox", "oob-outbox";
				#mbox-cells = <2>;
			};

			adi_bus: spi@32100000 {
				compatible = "sprd,sharkl5pro-adi";
				reg = <0 0x32100000 0 0x100000>;
				#address-cells = <1>;
				#size-cells = <0>;
			};

			ap_thm0: thermal@32200000 {
				compatible = "sprd,ums512-thermal";
				reg = <0 0x32200000 0 0x10000>;
				#address-cells = <1>;
				#size-cells = <0>;
				clock-names = "enable";
				clocks = <&aonapb_gate CLK_THM0_EB>;
				#thermal-sensor-cells = <1>;
				nvmem-cells = <&thm0_sign>, <&thm0_ratio>;
				nvmem-cell-names = "thm_sign_cal", "thm_ratio_cal";

				sensor@0 {
					reg = <0>;
					nvmem-cells = <&thm0_sen0>;
					nvmem-cell-names = "sen_delta_cal";
				};

				sensor@1 {
					reg = <1>;
					nvmem-cells = <&thm0_sen1>;
					nvmem-cell-names = "sen_delta_cal";
				};

				sensor@2 {
					reg = <2>;
					nvmem-cells = <&thm0_sen2>;
					nvmem-cell-names = "sen_delta_cal";
				};

				sensor@3 {
					reg = <3>;
					nvmem-cells = <&thm0_sen3>;
					nvmem-cell-names = "sen_delta_cal";
				};

				sensor@4 {
					reg = <4>;
					nvmem-cells = <&thm0_sen4>;
					nvmem-cell-names = "sen_delta_cal";
				};
			};

			ap_thm1: thermal@32210000 {
				compatible = "sprd,ums512-thermal";
				reg = <0 0x32210000 0 0x10000>;
				#address-cells = <1>;
				#size-cells = <0>;
				clock-names = "enable";
				clocks = <&aonapb_gate CLK_THM1_EB>;
				#thermal-sensor-cells = <1>;
				nvmem-cells = <&thm1_sign>, <&thm1_ratio>;
				nvmem-cell-names = "thm_sign_cal", "thm_ratio_cal";

				sensor@0 {
					reg = <0>;
					nvmem-cells = <&thm1_sen0>;
					nvmem-cell-names = "sen_delta_cal";
				};

				sensor@1 {
					reg = <1>;
					nvmem-cells = <&thm1_sen1>;
					nvmem-cell-names = "sen_delta_cal";
				};

				sensor@2 {
					reg = <2>;
					nvmem-cells = <&thm1_sen2>;
					nvmem-cell-names = "sen_delta_cal";
				};

				sensor@3 {
					reg = <3>;
					nvmem-cells = <&thm1_sen3>;
					nvmem-cell-names = "sen_delta_cal";
				};

				sensor@4 {
					reg = <4>;
					nvmem-cells = <&thm1_sen4>;
					nvmem-cell-names = "sen_delta_cal";
				};

				sensor@5 {
					reg = <5>;
					nvmem-cells = <&thm1_sen5>;
					nvmem-cell-names = "sen_delta_cal";
				};
			};

			ap_thm2: thermal@32220000 {
				compatible = "sprd,ums512-thermal";
				reg = <0 0x32220000 0 0x10000>;
				#address-cells = <1>;
				#size-cells = <0>;
				clock-names = "enable";
				clocks = <&aonapb_gate CLK_THM2_EB>;
				#thermal-sensor-cells = <1>;
				nvmem-cells = <&thm2_sign>, <&thm2_ratio>;
				nvmem-cell-names = "thm_sign_cal", "thm_ratio_cal";

				sensor@0 {
					reg = <0>;
					nvmem-cells = <&thm2_sen0>;
					nvmem-cell-names = "sen_delta_cal";
				};
			};

			ap_efuse: efuse@32240000 {
				compatible = "sprd,ums312-efuse", "sprd,ums512-efuse";
				reg = <0 0x32240000 0 0x10000>;
				clock-names = "enable";
				hwlocks = <&hwlock 8>;
				clocks = <&aonapb_gate CLK_EFUSE_EB>;
			};

			pwms: pwm@32260000 {
				compatible = "sprd,sharkl5pro-pwm";
				reg = <0 0x32260000 0 0x10000>;
				clock-names = "pwm0", "enable0",
					      "pwm1", "enable1",
					      "pwm2", "enable2";
				clocks = <&aon_clk CLK_PWM0>, <&aonapb_gate CLK_PWM0_EB>,
					 <&aon_clk CLK_PWM1>, <&aonapb_gate CLK_PWM1_EB>,
					 <&aon_clk CLK_PWM2>, <&aonapb_gate CLK_PWM2_EB>;
				assigned-clocks = <&aon_clk CLK_PWM0>,
						  <&aon_clk CLK_PWM1>,
						  <&aon_clk CLK_PWM2>;
				assigned-clock-parents = <&ext_26m>,
							 <&ext_26m>,
							 <&ext_26m>;
				#pwm-cells = <2>;
			      };

			sprd_hardware_cpufreq: hardware-dvfs-platform {
				compatible = "sprd,hardware-cpufreq";
			};

			topdvfs_controller: topdvfsctrl@322a0000 {
				compatible = "sprd,sharkl5pro-topdvfs-dev", "sprd,topdvfs-dev", "syscon";
				sprd,syscon-enable = <&aon_apb_regs>;
				module-enable-cfg = <0x4 7>;
				reg = <0 0x322a0000 0 0x8000>;
				sprd,topdvfs-sysctrl = <&top_dvfs_apb_regs>;
				cpu-dcdc-cells = <&dcdc_cpu0>, <&dcdc_cpu1>;
				device-dcdc-cells = <&dcdc_mm>, <&dcdc_modem>;
				dcdc_cpu0: dcdc-cpu0{
					dcdc-cpu-dvfs-cfg = <&dvfs_dcdc_cpu0_cfg>;
					dvfs-blk-sd-syscon = <&pmu_apb_regs
						REG_PMU_APB_RF_DVFS_BLOCK_SHUTDOWN_CFG
						MASK_PMU_APB_RF_DCDC_CPU0_DVFS_BLOCK_SHUTDOWN_EN>;
				};

				dcdc_cpu1: dcdc-cpu1{
					dcdc-cpu-dvfs-cfg = <&dvfs_dcdc_cpu1_cfg>;
					dvfs-blk-sd-syscon = <&pmu_apb_regs
						REG_PMU_APB_RF_DVFS_BLOCK_SHUTDOWN_CFG
						MASK_PMU_APB_RF_DCDC_CPU1_DVFS_BLOCK_SHUTDOWN_EN>;
				};

				dcdc_mm: dcdc-mm {
					dcdc-dvfs-enable = <0x18 20 1>;
					dcdc-judge-vol-sw = <0x18 1 0x7 2>;
					dcdc-subsys-cells = <&audcp_sys>,
							<&gpu_sys>,
							<&mm_sys>;
					audcp_sys: audcp-sys {
						dcdc-subsys-tune-enable = <0x150 5 0>;
					};
					gpu_sys: gpu-sys {
						dcdc-subsys-tune-enable = <0x150 1 1>;
					};
					mm_sys: mm-sys {
						dcdc-subsys-tune-enable = <0x150 2 0>;
					};
				};

				dcdc_modem: dcdc-modem {
					dcdc-dvfs-enable = <0x3c 20 1>;
					dcdc-judge-vol-sw = <0x3c 1 0x7 2>;
					dcdc-subsys-cells = <&pubcp_sys>,
							<&wtlcp_sys>,
							<&ap_sys>;
					pubcp_sys: pubcp-sys {
						dcdc-subsys-tune-enable = <0x150 4 0>;
					};
					wtlcp_sys: wtlcp-sys {
						dcdc-subsys-tune-enable = <0x150 3 0>;
					};
					ap_sys: ap-sys {
						dcdc-subsys-tune-enable = <0x150 0 1>;
					};
				};
			};

			cpudvfs_dev: cpudvfs-dev@322a8000 {
				compatible = "sprd,sharkl5pro-cpudvfs";
				reg = <0 0x322a8000 0 0x1000>;
				enable-syscon = <&aon_apb_regs REG_AON_APB_RF_APB_EB1 MASK_AON_APB_RF_DVFS_TOP_EB>;
				topdvfs-controller = <&topdvfs_controller>;
				host-cluster-cells = <&lit_core_cluster>,<&big_core_cluster>;
				slave-cluster-cells = <&scu_cluster>, <&periph_cluster>,<&gic_cluster>;
				mpll-cells = <&mpll_0>, <&mpll_1>, <&mpll_2>;
				lit_core_cluster: lit-core-cluster {
					belong-dcdc-cell = <0>;
					/*sel, div, vol, vote_scu, vote_peri, vote_gic, mpllx*/
					lit_core_cluster_tbl = <
						0 0 0 0 0 0 0
						1 1 0 1 1 1 0
						2 1 0 2 1 1 0
						3 0 0 2 1 1 0
						3 0 0 3 1 1 1
						1 0 1 4 1 1 0
						3 0 2 5 4 4 2
						2 0 3 6 4 4 0
						3 0 4 7 4 5 3
						3 0 5 8 4 5 4
						3 0 6 9 5 5 5
						>;
					lit_core_cluster_tbl_ff = <
						0 0 0 0 0 0 0
						1 1 0 1 1 1 0
						2 1 1 2 2 2 0
						3 0 1 3 2 3 0
						3 0 1 4 3 4 1
						1 0 1 5 4 4 0
						3 0 2 6 4 4 2
						2 0 2 7 4 4 0
						3 0 2 8 4 5 3
						3 0 2 9 5 5 4
						>;
					lit_core_cluster_tbl_ff_65 = <
						0 0 0 0 0 0 0
						1 1 0 1 1 1 0
						2 1 1 2 2 2 0
						3 0 1 3 2 3 0
						3 0 1 4 3 4 1
						1 0 1 5 4 4 0
						3 0 2 6 4 4 2
						2 0 2 7 4 4 0
						3 0 2 8 4 5 3
						3 0 2 9 5 5 4
						>;
					};

				big_core_cluster:big-core-cluster {
					belong-dcdc-cell = <1>;
					/*sel, div, vol, vote_scu, vote_peri, vote_gic, mpllx*/
					big_core_cluster_tbl = <
						0 0 0 0 0 0 0
						1 0 0 3 1 1 0
						3 0 1 5 4 4 0
						2 0 2 6 4 4 0
						3 0 3 7 4 5 1
						3 0 4 8 4 5 3
						3 0 5 9 5 5 4
						>;
					big_core_cluster_tbl_ff = <
						0 0 0 0 0 0 0
						1 0 0 3 3 4 0
						3 0 1 5 4 4 0
						2 0 2 6 4 4 0
						3 0 2 7 4 5 1
						3 0 2 8 4 5 2
						3 0 2 9 5 5 3
						>;
					big_core_cluster_tbl_ff_65 = <
						0 0 0 0 0 0 0
						1 0 0 3 3 4 0
						3 0 1 5 4 4 0
						2 0 2 6 4 4 0
						3 0 2 7 4 5 1
						3 0 2 8 4 5 2
						3 0 2 9 5 5 3
						>;
				};

				scu_cluster: scu-cluster {
					belong-dcdc-cell = <0>;
					/*sel div vol ace_div mpllx */
					scu_cluster_tbl = <
						0 0 0 0 0
						3 0 0 1 0
						3 0 0 1 1
						1 0 0 1 0
						3 0 1 1 2
						3 0 2 1 3
						3 0 3 1 4
						3 0 4 1 5
						3 0 5 1 6
						3 0 6 1 7
						>;
					scu_cluster_tbl_ff = <
						0 0 0 0 0
						3 0 0 1 0
						3 0 1 1 1
						1 0 1 1 0
						3 0 1 1 2
						3 0 1 1 3
						3 0 2 1 4
						3 0 2 1 5
						3 0 2 1 6
						3 0 2 1 7
						>;
					scu_cluster_tbl_ff_65 = <
						0 0 0 0 0
						3 0 0 1 0
						3 0 1 1 1
						1 0 1 1 0
						3 0 1 1 2
						3 0 1 1 3
						3 0 2 1 4
						3 0 2 1 5
						3 0 2 1 6
						3 0 2 1 7
						>;
				};

				periph_cluster:periph-cluster {
					belong-dcdc-cell = <0>;
					/*sel div vol*/
					periph_cluster_tbl = <
						0 0 0
						1 0 0
						2 1 2
						3 1 2
						2 0 2
						3 0 6
						>;
					periph_cluster_tbl_ff = <
						0 0 0
						1 0 0
						2 1 1
						3 1 1
						2 0 1
						3 0 2
						>;
					periph_cluster_tbl_ff_65 = <
						0 0 0
						1 0 0
						2 1 1
						3 1 1
						2 0 1
						3 0 2
						>;
				};

				gic_cluster: gic-cluster {
					belong-dcdc-cell = <0>;
					/*sel div vol*/
					gic_cluster_tbl = <
						0 0 0
						1 0 0
						2 1 2
						3 1 2
						2 0 2
						3 0 2
						>;
					gic_cluster_tbl_ff = <
						0 0 0
						1 0 0
						2 1 1
						3 1 1
						2 0 1
						3 0 1
						>;
					gic_cluster_tbl_ff_65 = <
						0 0 0
						1 0 0
						2 1 1
						3 1 1
						2 0 1
						3 0 1
						>;
				};

				mpll_0: mpll-ananke{
					mpll-sel-syscon = <&anlg_phy_g3_regs REG_ANLG_PHY_G3_RF_ANALOG_MPLL0_REG_SEL_CFG_0
						(MASK_ANLG_PHY_G3_RF_DBG_SEL_ANALOG_MPLL0_MPLL0_POSTDIV |
						MASK_ANLG_PHY_G3_RF_DBG_SEL_ANALOG_MPLL0_MPLL0_ICP |
						MASK_ANLG_PHY_G3_RF_DBG_SEL_ANALOG_MPLL0_MPLL0_N)>;
				};

				mpll_1: mpll-prometheus{
					mpll-sel-syscon = <&anlg_phy_g2_regs REG_ANLG_PHY_G2_RF_ANALOG_MPLL1_REG_SEL_CFG_0
						(MASK_ANLG_PHY_G2_RF_DBG_SEL_ANALOG_MPLL1_MPLL1_POSTDIV |
						MASK_ANLG_PHY_G2_RF_DBG_SEL_ANALOG_MPLL1_MPLL1_ICP |
						MASK_ANLG_PHY_G2_RF_DBG_SEL_ANALOG_MPLL1_MPLL1_N)>;
				};

				mpll_2: mpll-scu{
					mpll-sel-syscon = <&anlg_phy_g3_regs REG_ANLG_PHY_G3_RF_ANALOG_MPLL2_REG_SEL_CFG_0
						(MASK_ANLG_PHY_G3_RF_DBG_SEL_ANALOG_MPLL2_MPLL2_POSTDIV |
						MASK_ANLG_PHY_G3_RF_DBG_SEL_ANALOG_MPLL2_MPLL2_ICP |
						MASK_ANLG_PHY_G3_RF_DBG_SEL_ANALOG_MPLL2_MPLL2_N)>;
				};
			};

			apb_bm: apb-busmonitor@32370000 {
				compatible = "sprd,apb-busmonitor";
				reg = <0 0x32370000 0 0x1000>;
				interrupts = <GIC_SPI 102 IRQ_TYPE_LEVEL_HIGH>;
				sprd,target-addr = <0 0>;
				sprd,target-data = <0 0>;
			 };

			timer@322e0000 {
				compatible = "sprd,syst-timer";
				reg = <0 0x322e0000 0 0x10>;
			};

			watchdog@322f0000 {
				compatible = "sprd,wdt-r2p0-fiq";
				reg = <0 0x322f0000 0 0x10000>;
				interrupts = <GIC_SPI 79 IRQ_TYPE_LEVEL_HIGH>;
				timeout-sec = <12>;
				clock-names = "enable", "rtc_enable";
				clocks = <&aonapb_gate CLK_APCPU_WDG_EB>,
				       <&aonapb_gate CLK_AC_WDG_RTC_EB>;
			};

			hsphy: hsphy@323b0000 {
				compatible = "sprd,sharkl5-phy", "sprd,sharkl5pro-phy";
				sprd,syscon-enable = <&aon_apb_regs>;
				sprd,syscon-anag2 = <&anlg_phy_g2_regs>;
				sprd,vdd-voltage = <3300000>;
				#phy-cells = <0>;
			};

			pin_controller: pinctrl@32450000 {
				compatible = "sprd,sharkl5Pro-pinctrl";
				reg = <0 0x32450000 0 0x3000>;
				vbc_iis3_0: vbc-iis3-0 {
					pins = "SHARKL5PRO_IIS_INF0_SYS_SEL";
					sprd,control = <0xe>;
				};

				vbc_iism0_0: vbc-iism0-0 {
					pins = "SHARKL5PRO_IIS_INF0_SYS_SEL";
					sprd,control = <0xf>;
				};

				vbc_iis_to_pad: vbc-iis-to-pad {
					pins = "SHARKL5PRO_VBC_IIS_INF_SYS_SEL";
					sprd,control = <0x0>;
				};

				vbc_iis_to_aon_usb: vbc-iis-to-aon-usb {
					pins = "SHARKL5PRO_VBC_IIS_INF_SYS_SEL";
					sprd,control = <0x1>;
				};

				vbc_iism0_1: vbc-iism0-1 {
					pins = "SHARKL5PRO_IIS_INF1_SYS_SEL";
					sprd,control = <0xf>;
				};

				vbc_iism0_3: vbc-iism0-3 {
					pins = "SHARKL5PRO_IIS_INF3_SYS_SEL";
					sprd,control = <0xf>;
				};

				vbc_iis0_3: vbc-iis0-3 {
					pins = "SHARKL5PRO_IIS_INF3_SYS_SEL";
					sprd,control = <0xb>;
				};

				vbc_iis1_3: vbc-iis1-3 {
					pins = "SHARKL5PRO_IIS_INF3_SYS_SEL";
					sprd,control = <0xc>;
				};

				vbc_iis2_3: vbc-iis2-3 {
					pins = "SHARKL5PRO_IIS_INF3_SYS_SEL";
					sprd,control = <0xd>;
				};

				vbc_iis3_3: vbc-iis3-3 {
					pins = "SHARKL5PRO_IIS_INF3_SYS_SEL";
					sprd,control = <0xe>;
				};

				ap_iis0_3: ap-iis0-3 {
					pins = "SHARKL5PRO_IIS_INF3_SYS_SEL";
					sprd,control = <0x0>;
				};
			};

			djtag: djtag@324e0000 {
				compatible = "sprd,djtag";
				status = "okay";
				reg = <0 0x324e0000 0 0x1000>;
				syscon-names = "soft_rst";
				syscon = <&aon_apb_regs REG_AON_APB_RF_APB_RST3
					MASK_AON_APB_RF_DJTAG_SOFT_RST>;
				clock-names = "enable", "tck";
				clocks = <&aonapb_gate CLK_DJTAG_EB>,
					<&aonapb_gate CLK_DJTAG_TCK_EB>;
				hwlocks = <&hwlock 10>;
				hwlock-names = "djtag";

				#address-cells = <1>;
				#size-cells = <0>;

				aon-busmonitor@8{
					compatible = "sprd,sharkl5pro-busmonitor";
					interrupts = <GIC_SPI 81
						IRQ_TYPE_LEVEL_HIGH>;
					reg = <0x8>;
					sprd,bm-num = <6>;
					sprd,bm-name =
						"AP", "WTLCP", "AUDCP", "PUBCP",
						"USBOTG", "CM4";
					sprd,bm-type =
						<AXI>, <AXI>, <AXI>,
						<AXI>, <AXI>, <AXI>;
					sprd,bm-dap = <0>, <1>, <2>, <3>,
						<4>, <5>;
					sprd,bm-config =
						<DISABLE MON_WRITE MON_INSIDE>,
						<DISABLE MON_WRITE MON_INSIDE>,
						<DISABLE MON_WRITE MON_INSIDE>,
						<DISABLE MON_WRITE MON_INSIDE>,
						<DISABLE MON_WRITE MON_INSIDE>,
						<DISABLE MON_WRITE MON_INSIDE>;
					sprd,bm-id =
						<DISABLE 0 AXIID>,
						<DISABLE 0 AXIID>,
						<DISABLE 0 AXIID>,
						<DISABLE 0 AXIID>,
						<DISABLE 0 AXIID>,
						<DISABLE 0 AXIID>;
					sprd,bm-ranges =
						<0 0>,
						<0 0>,
						<0 0>,
						<0 0>,
						<0 0>,
						<0 0>;
				};
			};

			modem_dbg_log: modem-dbg-log@324f0000 {
				compatible = "sprd,dbg-log-sharkl5", "sprd,dbg-log-sharkl5pro";
				reg = <0 0x324f0000 0 0x4000>;
				sprd,syscon-mm-ahb = <&mm_ahb_regs>;
				sprd,syscon-dsi-apb = <&anlg_phy_g10_regs>;
				sprd,ch-name = "TRAINING", "WTL", "MADR", "TPIU", "DBUS", "WCN";
				sprd,ch-index = <15 1 0 2 3 4>;
				sprd,dcfix;
				sprd,mm;
				sprd,mipi-l5pro = <1>;
				power-domains = <&mm_domain>;
				status = "okay";
			};

			hwlock: hwspinlock@327f0000 {
				compatible = "sprd,hwspinlock-r3p0";
				reg = <0 0x327f0000 0 0x10000>;
				#hwlock-cells = <1>;
				clock-names = "enable";
				clocks = <&aonapb_gate CLK_SPLK_EB>;
			};

			usb: usb@5fff0000 {
				compatible = "sprd,sharkl5pro-musb", "sprd,sharkl3-musb";
				reg = <0 0x5fff0000 0 0x2000>;
				interrupts = <GIC_SPI 69 IRQ_TYPE_LEVEL_HIGH>;
				interrupt-names = "mc";
				clocks = <&aonapb_gate CLK_OTG_UTMI_EB>;
				clock-names = "core_clk";
				usb-phy = <&hsphy>;
				phy-names = "usb";
				dr-mode = "peripheral";
				multipoint = "true";
				wakeup-source;
			};
		};

		agcp {
			compatible = "simple-bus";
			#address-cells = <2>;
			#size-cells = <2>;
			ranges;

			vbc_v4: vbc@33480000 {
				compatible = "unisoc,sharkl5-vbc", "unisoc,sharkl5pro-vbc";
				#sound-dai-cells = <1>;
				reg = <0 0x33480000 0 0x1000>;
				sprd,syscon-agcp-ahb = <&audcp_ahb_regs>;
				sprd,vbc-phy-offset = <0x32000000>;
				/* iis pin map */
				pinctrl-names =
				/* iis interface 0 */
				"vbc_iis3_0", "vbc_iism0_0",
				"vbc_iis_to_pad", "vbc_iis_to_aon_usb", "vbc_iism0_1", "vbc_iism0_3",
				"vbc_iis0_3", "vbc_iis1_3", "vbc_iis2_3", "vbc_iis3_3", "ap_iis0_3";
				pinctrl-0 = <&vbc_iis3_0>;
				pinctrl-1 = <&vbc_iism0_0>;
				pinctrl-2 = <&vbc_iis_to_pad>;
				pinctrl-3 = <&vbc_iis_to_aon_usb>;
				pinctrl-4 = <&vbc_iism0_1>;
				pinctrl-5 = <&vbc_iism0_3>;
				pinctrl-6 = <&vbc_iis0_3>;
				pinctrl-7 = <&vbc_iis1_3>;
				pinctrl-8 = <&vbc_iis2_3>;
				pinctrl-9 = <&vbc_iis3_3>;
				pinctrl-10 = <&ap_iis0_3>;
			};

			mcdt@33490000{
				compatible = "unisoc,sharkl5-mcdt", "unisoc,sharkl5pro-mcdt";
				reg = <0 0x33490000 0 0x170>;
				interrupts = <GIC_SPI 182 IRQ_TYPE_LEVEL_HIGH>;
				sprd,ap-addr-offset = <0x32000000>;
				sprd,syscon-agcp-ahb = <&audcp_ahb_regs>;
			};

			agcp_dma: dma-controller@33580000 {
				compatible = "sprd,sharkl5pro-dma", "sprd,sc9860-dma";
				reg = <0 0x33580000 0 0x4000>;
				interrupts = <GIC_SPI 180 IRQ_TYPE_LEVEL_HIGH>;
				#dma-cells = <1>;
				#dma-channels = <32>;
				clock-names = "enable", "ashb_eb";
				clocks = <&audcpahb_gate CLK_AUDCP_DMA_AP_EB>,
					<&audcpahb_gate CLK_AUDCP_DMA_AP_ASHB_EB>;
			};

			sprd_audio_codec_dig: audio-codec@33750000 {
				compatible = "unisoc,audio-codec-dig-agcp";
				reg = <0 0x33750000 0 0x1000>;
				sprd,syscon-agcp-ahb = <&audcp_ahb_regs>;
			};

			agdsp-access {
				compatible = "unisoc,agdsp-access";
				sprd,syscon-agcp-ahb = <&aon_apb_regs>;
				sprd,syscon-pmu-apb = <&pmu_apb_regs>;
				audcp_pmu_sleep_ctrl = <&pmu_apb_regs REG_PMU_APB_RF_SLEEP_CTRL
							MASK_PMU_APB_RF_AUDCP_DEEP_SLEEP>;
				audcp_pmu_slp_status = <&pmu_apb_regs REG_PMU_APB_RF_SLEEP_STATUS
							MASK_PMU_APB_RF_AUDCP_SLP_STATUS>;
				audcp_pmu_pwr_status4 = <&pmu_apb_regs REG_PMU_APB_RF_PWR_STATUS4_DBG
							MASK_PMU_APB_RF_PD_AUDCP_SYS_STATE>;
				audcp_pmu_pwr_status3 = <&pmu_apb_regs REG_PMU_APB_RF_PWR_STATUS3_DBG
							MASK_PMU_APB_RF_PD_AUDCP_AUDDSP_STATE>;
				ap_access_ena = <&aon_apb_regs REG_AON_APB_RF_AUDCP_CTRL
							MASK_AON_APB_RF_AP_2_AUD_ACCESS_EN>;
				sprd,ddr-addr-offset = <0x0>;
				sprd,auto_agcp_access = <0>;
			};
		};

		pub {
			compatible = "simple-bus";
			#address-cells = <2>;
			#size-cells = <2>;
			ranges;

			mpu: dmc-mpu@31030000 {
				compatible = "sprd,sharkl5pro-dmc-mpu";
				reg = <0 0x31030000 0 0x10000>;
				interrupts = <GIC_SPI 111 IRQ_TYPE_LEVEL_HIGH>;
				syscon-names = "irq_clr", "irq_en";
				mpu-irq-clr-syscon = <&pub_apb_regs
					REG_PUB_APB_RF_PUB_INT_CTRL
					MASK_PUB_APB_RF_DMC_MPU_VIO_INT_CLR>;
				mpu-irq-en-syscon = <&pub_apb_regs
					REG_PUB_APB_RF_PUB_INT_CTRL
					MASK_PUB_APB_RF_DMC_MPU_VIO_INT_EN>;
				sprd,channel-num = <7>;
				sprd,mpu-num = <16>;
				sprd,channel-names =
					"CPU", "GPU", "DPU/DCAM","ISP",
					"AP/VSP/AON", "WTLCP", "PUBCP/AUDCP",
					"SHARED0", "SHARED1", "SHARED2",
					"SHARED3", "SHARED4", "SHARED5",
					"SHARED6", "SHARED7", "SHARED8";
				sprd,ranges = <0 0 0 0>, <0 0 0 0>, <0 0 0 0>,
					<0 0 0 0>, <0 0 0 0>, <0 0 0 0>,
					<0 0 0 0>, <0 0 0 0>, <0 0 0 0>,
					<0 0 0 0>, <0 0 0 0>, <0 0 0 0>,
					<0 0 0 0>, <0 0 0 0>, <0 0 0 0>,
					<0 0 0 0>;
				sprd,chn-config =
					<DISABLE MON_INSIDE MON_WRITE>,
					<DISABLE MON_INSIDE MON_WRITE>,
					<DISABLE MON_INSIDE MON_WRITE>,
					<DISABLE MON_INSIDE MON_WRITE>,
					<DISABLE MON_INSIDE MON_WRITE>,
					<DISABLE MON_INSIDE MON_WRITE>,
					<DISABLE MON_INSIDE MON_WRITE>,
					<DISABLE MON_INSIDE MON_WRITE>,
					<DISABLE MON_INSIDE MON_WRITE>,
					<DISABLE MON_INSIDE MON_WRITE>,
					<DISABLE MON_INSIDE MON_WRITE>,
					<DISABLE MON_INSIDE MON_WRITE>,
					<DISABLE MON_INSIDE MON_WRITE>,
					<DISABLE MON_INSIDE MON_WRITE>,
					<DISABLE MON_INSIDE MON_WRITE>,
					<DISABLE MON_INSIDE MON_WRITE>;
				sprd,id-config =
					<MPUID 0 0xffff>, <MPUID 0 0xffff>,
					<MPUID 0 0xffff>, <MPUID 0 0xffff>,
					<MPUID 0 0xffff>, <MPUID 0 0xffff>,
					<MPUID 0 0xffff>, <MPUID 0 0xffff>,
					<MPUID 0 0xffff>, <MPUID 0 0xffff>,
					<MPUID 0 0xffff>, <MPUID 0 0xffff>,
					<MPUID 0 0xffff>, <MPUID 0 0xffff>,
					<MPUID 0 0xffff>, <MPUID 0 0xffff>;
				sprd,port-map = <0>, <1>, <2>, <3>, <4>,
					<5>, <6>, <0>, <0>, <0>,
					<0>, <0>, <0>, <0>, <0>,
					<0>;
				sprd,ddr-offset = <0x80000000>;
				status = "disabled";
			};

			ptm_trace: ptm@31060000 {
				compatible = "sprd,sharkl5pro-ptm";
				reg = <0x0 0x31060000 0x0 0x10000>,
					<0x0 0x3c002000 0x0 0x1000>,
					<0x0 0x3c003000 0x0 0x1000>,
					<0x0 0x3c006000 0x0 0x1000>;
				interrupts = <GIC_SPI 109 IRQ_TYPE_LEVEL_HIGH>;
				clock-names = "clk_cs","cs_src";
				clocks = <&aon_clk CLK_CSSYS>,
					<&pll2 CLK_TWPLL_153M6>;
				sprd,funnel-port = <3>;
				sprd,ddr-chn = <7>;
				sprd,chn-name = "CPU", "GPU", "DPU/DCAM",
					"ISP", "AP/VSP/AON", "WTLCP",
					"PUBCP/AUDCP";
			};

			dmc_controller: dmc-controller@31050000 {
				compatible = "sprd,pub-dmc";
				reg = <0x0 0x3000 0x0 0x100>, /* proc res */
					<0x0 0x31050000 0x0 0x7000>; /* mon res */
			};
		};
	};

	sipc: sipc-virt {
		compatible = "unisoc,sipc-virt-bus";
		#address-cells = <1>;
		#size-cells = <0>;
	};

	sprd_pcm: sprd-pcm-audio {
		compatible = "unisoc,sharkl5-pcm-platform",
			"unisoc,sharkl5pro-pcm-platform";
		#sound-dai-cells = <0>;
		/* agcp dma_ap */
		dmas = <&agcp_dma 1 &agcp_dma 2
			&agcp_dma 3 &agcp_dma 4
			&agcp_dma 17 &agcp_dma 18
			&agcp_dma 15 &agcp_dma 16
			&agcp_dma 14 &agcp_dma 8
			&agcp_dma 12 &agcp_dma 9
			&agcp_dma 13 &agcp_dma 8
			&agcp_dma 11 &agcp_dma 6
			&agcp_dma 14 &agcp_dma 14
			&agcp_dma 12 &agcp_dma 6>;

		dma-names =
			"normal_p_l", "normal_p_r",
			"normal_c_l", "normal_c_r",
			"normal23_p_l", "normal23_p_r",
			"normal23_c_l", "normal23_c_r",
			"dspcap_c", "a2dppcm_p",
			"voice_c","fast_p",
			"loop_c", "loop_p",
			"voip_c", "voip_p",
			/* dspfmcap_c and dspbtscocap_c same as dspcap_c */
			"dspfmcap_c", "dspbtscocap_c",
			/* recognise_c same as voice_c, voice_pcm_p same as loop_p */
			"recognise_c", "voice_pcm_p";
	};

	sprd_compr: sprd-compr-audio {
		compatible = "unisoc,sharkl5-compress-platform",
			"unisoc,sharkl5pro-compress-platform";
		#sound-dai-cells = <0>;
		dmas = <&agcp_dma 5 &agcp_dma 0>;
		dma-names = "compr_dma_stage0", "compr_dma_stage1";
	};

	sprd_fe_dai: sprd-fe-dai {
		compatible = "unisoc,fe-dai";
		#sound-dai-cells = <1>;
	};

	sprd_route_pcm: sprd-routing-pcm {
		compatible = "unisoc,pcm-routing";
		#sound-dai-cells = <0>;
	};

	audio-sipc{
		compatible = "unisoc,audio_sipc";
		/* <&mailbox  channel_id  is_no_wakeup(default 0)> */
		mboxes = <&mailbox 5 0>;
	};

	audio-mem-mgr {
		compatible = "unisoc,audio-mem-sharkl5", "unisoc,audio-mem-sharkl5pro";
		/*
		 * base is 0x87400000 for sharkl5
		 * 1. reserved ddr layout total 4M:
		 * 3M (ap used. include dma data,dma node(dynamic),
		 * dsp log(65K), dsp pcm(65K)) + 1k(cmd param) 2K + 16b(cmd) +
		 * 1K AUDIO_STRUCT_PARA + 1K(nxp/cvs) + dsp used(4k)) +
		 * 0.5M dsp memdump
		 */
		ddr32-ap-dsp-map-offset = <0x0>;
		/*
		 * 3M for dynamic alloc, 0x87400000 - 0x87700000 ddr32-dma,
		 * 1M for other
		 */
		sprd,ddr32-dma = <0x87400000 0x300000>;
		/* 512K,  0x87700000 - 0x87780000*/
		sprd,ddr32-dspmemdump = <0x87700000 0x80000>;
		/* 1K cmd para, 0x87780000 - 0x87780400 */
		sprd,cmdaddr = <0x87780000 0x400>;
		/* 2K + 16byte,0x87780400 - 0x87780e10 */
		sprd,smsg-addr = <0x87780400 0xa10>;
		/* 1K AUDIO_STRUCT_PARA 0x87780e10 - 0x87781210*/
		sprd,shmaddr-aud-str = <0x87780e10 0x400>;
		/* 5K DSP_VBC_PARA, 0x87781210 - 0x87782610 */
		sprd,shmaddr-dsp-vbc = <0x87781210 0x1400>;
		/* 1K nxp/cvs para, 0x87782610 - 0x87782a10 */
		sprd,shmaddr-nxp = <0x87782610 0x400>;
		/* 2K ivsence smartpa param, 0x87782a10 - 0x87783210 */
		sprd,shmaddr-dsp-smartpa = <0x87782a10 0x1000>;
		/* 1K REG DUMP, 0x87783a10 - 0x87783a50 */
		sprd,shmaddr-reg-dump = <0x87783a10 0x400>;

		/* 2. iram layout total 32K */
		sprd,iram-ap-base =  <0x33800000>;
		sprd,iram-dsp-base = <0x01800000>;
		/* mp3 23K */
		sprd,offload-addr = <0x33800000 0x5c00>;
		/* 0.5 reserved */
		/* normal capture total 8.5K */
		/* 0x200 (0.5K) */
		sprd,normal-captue-linklilst-node1 =<0x33805e00 0x200>;
		/*
		 * normal capture data
		 * 7.5K
		 * pagesize(4K) aligned
		 */
		sprd,normal-captue-data =<0x33806000 0x1e00>;
		/* 0x200(0.5K) */
		sprd,normal-captue-linklilst-node2 =<0x33807e00 0x200>;
		/* audcp aon iram */
		sprd,audcp-aon-iram = <&audcp_iram_reserved>;
	};

	audio-dsp-dump@0 {/* audio dsp log */
		compatible = "unisoc,audio_dsp_log";
		sprd-usemem-type =<0x5>;
		sprd-dst = /bits/ 8 <1>; /* AGDSP */
		sprd-channel =/bits/ 8 <4>;
		sprd-rxblocknum=<0x8>;
		sprd-rxblocksize=<0x2000>;
	};

	audio-dsp-dump@1 {/* audio dsp pcm */
		compatible = "unisoc,audio_dsp_pcm";
		sprd-usemem-type =<0x5>;
		sprd-dst = /bits/ 8 <1>; /* AGDSP */
		sprd-channel =/bits/ 8 <3>;
		sprd-rxblocknum=<0x8>;
		sprd-rxblocksize=<0x2000>;
	};

	audio-dsp-dump@2 {/* audio dsp log */
		compatible = "unisoc,audio_dsp_mem";
		sprd-usemem-type =<0x9>;
		sprd-usemem-bytes =<0x80000>;
		sprd-dst = /bits/ 8 <1>; /* AGDSP */
		sprd-channel =/bits/ 8 <5>;
		/* for cmd para addr */
		sprd,dspdumpmem = <0x33000000 0x10000
				   0xa400 0x1000
				   0x89300000 0x5f000>;
	};

	audio_pipe_voice {
		compatible = "unisoc,audio_pipe_voice";
		sprd,writesync = <0>;
		sprd,maxuserwritebufsize = <0>;
		sprd,channel = <2>;
	};

	audio_pipe_effect {
		compatible = "unisoc,audio_pipe_effect";
		sprd,writesync = <1>;
		sprd,maxuserwritebufsize = <1024>;
		sprd,channel = <8>;
	};

	audio_pipe_voiceproc {
		compatible = "unisoc,audio_pipe_recordproc";
		sprd,writesync = <1>;
		sprd,maxuserwritebufsize = <1024>;
		sprd,channel = <9>;
	};

	audio_pipe_bthal {
		compatible = "unisoc,audio_pipe_bthal";
		sprd,writesync = <0>;
		sprd,maxuserwritebufsize = <0>;
		sprd,channel = <11>;
	};

	audiocp_dvfs {
		compatible = "unisoc,sharkl5-audcp-dvfs", "unisoc,sharkl5pro-audcp-dvfs";
		sprd,channel = <10>;
	};

	audiocp_boot {
		compatible = "unisoc,sharkl5-audcp-boot", "unisoc,sharkl5pro-audcp-boot";
		sysshutdown = <&pmu_apb_regs REG_PMU_APB_RF_PD_AUDCP_SYS_CFG MASK_PMU_APB_RF_PD_AUDCP_SYS_FORCE_SHUTDOWN>;
		coreshutdown = <&pmu_apb_regs REG_PMU_APB_RF_PD_AUDCP_AUDDSP_CFG MASK_PMU_APB_RF_PD_AUDCP_AUDDSP_AUTO_SHUTDOWN_EN>;
		deepsleep = <&pmu_apb_regs REG_PMU_APB_RF_SLEEP_CTRL MASK_PMU_APB_RF_AUDCP_FORCE_DEEP_SLEEP>;
		corereset = <&pmu_apb_regs REG_PMU_APB_RF_CP_SOFT_RST MASK_PMU_APB_RF_AUDCP_AUDDSP_SOFT_RST>;
		sysreset = <&pmu_apb_regs REG_PMU_APB_RF_CP_SOFT_RST MASK_PMU_APB_RF_AUDCP_SYS_SOFT_RST>;
		reset_sel = <&pmu_apb_regs REG_PMU_APB_RF_SOFT_RST_SEL MASK_PMU_APB_RF_SOFT_RST_SEL>;
		sysstatus = <&pmu_apb_regs REG_PMU_APB_RF_PWR_STATUS4_DBG MASK_PMU_APB_RF_PD_AUDCP_SYS_STATE>;
		corestatus = <&pmu_apb_regs REG_PMU_APB_RF_PWR_STATUS3_DBG MASK_PMU_APB_RF_PD_AUDCP_AUDDSP_STATE>;
		sleepstatus = <&pmu_apb_regs REG_PMU_APB_RF_SLEEP_STATUS MASK_PMU_APB_RF_AUDCP_SLP_STATUS>;
		bootprotect = <&aon_apb_regs REG_AON_APB_RF_AUDCP_BOOT_PROT MASK_AON_APB_RF_REG_PROT_VAL>;
		bootvector = <&aon_apb_regs REG_AON_APB_RF_AUDCP_DSP_CTRL0 MASK_AON_APB_RF_AUDCP_DSP_BOOT_VECTOR>;
		bootaddress_sel = <&aon_apb_regs REG_AON_APB_RF_AUDCP_DSP_CTRL1 MASK_AON_APB_RF_AUDCP_DSP_BOOT>;
	};

	apipe-pcm {
		compatible = "unisoc,apipe";
	};

	apipe-cmd-in {
		compatible = "unisoc,apipe";
	};

	apipe-cmd-out {
		compatible = "unisoc,apipe";
	};

	ext_26m: ext-26m {
		compatible = "fixed-clock";
		#clock-cells = <0>;
		clock-frequency = <26000000>;
		clock-output-names = "ext-26m";
	};

	ext_32k: ext-32k {
		compatible = "fixed-clock";
		#clock-cells = <0>;
		clock-frequency = <32768>;
		clock-output-names = "ext-32k";
	};

	ext_4m: ext-4m {
		compatible = "fixed-clock";
		#clock-cells = <0>;
		clock-frequency = <4000000>;
		clock-output-names = "ext-4m";
	};

	rco_100m: rco-100m {
		compatible = "fixed-clock";
		#clock-cells = <0>;
		clock-frequency = <100000000>;
		clock-output-names = "rco-100m";
	};

	dphy_273m: dphy-273m {
		compatible = "fixed-clock";
		#clock-cells = <0>;
		clock-frequency = <273000000>;
		clock-output-names = "dphy-273m";
	};

	dphy_204m8: dphy-204m8 {
		compatible = "fixed-clock";
		#clock-cells = <0>;
		clock-frequency = <204800000>;
		clock-output-names = "dphy-204m8";
	};

	cache_efuse: efuse@800 {
		compatible = "sprd,ums312-cache-efuse", "sprd,ums512-cache-efuse";
		#address-cells = <1>;
		#size-cells = <1>;
		reg = <0 0x800 0 0x3ff>;

		uid_start: uid-start@5c{
			reg = <0x5c 0x4>;
		};

		uid_end: uid-end@58{
			reg = <0x58 0x4>;
		};

		thm0_sign: thm0-sign@38 {
			reg = <0x38 0x1>;
			bits = <0 1>;
		};

		thm0_ratio: thm0-ratio@38 {
			reg = <0x38 0x1>;
			bits = <1 7>;
		};

		thm0_sen0: thm0-sen0@39 {
			reg = <0x39 0x1>;
			bits = <0 8>;
		};

		thm0_sen1: thm0-sen1@41 {
			reg = <0x41 0x1>;
			bits = <0 8>;
		};

		thm0_sen2: thm0-sen2@40 {
			reg = <0x40 0x1>;
			bits = <0 8>;
		};

		thm0_sen3: thm0-sen3@43 {
			reg = <0x43 0x1>;
			bits = <0 8>;
		};

		thm0_sen4: thm0-sen4@42 {
			reg = <0x42 0x1>;
			bits = <0 8>;
		};

		thm1_sign: thm1-sign@3c {
			reg = <0x3c 0x1>;
			bits = <0 1>;
		};

		thm1_ratio: thm1-ratio@3c {
			reg = <0x3c 0x1>;
			bits = <1 7>;
		};

		thm1_sen0: thm1-sen0@3d {
			reg = <0x3d 0x1>;
			bits = <0 8>;
		};

		thm1_sen1: thm1-sen1@2f {
			reg = <0x2f 0x1>;
			bits = <0 8>;
		};

		thm1_sen2: thm1-sen2@2e {
			reg = <0x2e 0x1>;
			bits = <0 8>;
		};

		thm1_sen3: thm1-sen3@29 {
			reg = <0x29 0x1>;
			bits = <0 8>;
		};

		thm1_sen4: thm1-sen4@28 {
			reg = <0x28 0x1>;
			bits = <0 8>;
		};

		thm1_sen5: thm1-sen4@2b {
			reg = <0x2b 0x1>;
			bits = <0 8>;
		};

		thm2_sign: thm2-sign@3e {
			reg = <0x3e 0x1>;
			bits = <0 1>;
		};

		thm2_ratio: thm2-ratio@3e {
			reg = <0x3e 0x1>;
			bits = <1 7>;
		};

		thm2_sen0: thm2-sen0@3f {
			reg = <0x3f 0x1>;
			bits = <0 8>;
		};

		dvfs_bin_cpu0: dvfs-bin@17 {
			reg = <0x17 0x1>;
			bits = <0 3>;
		};

		dvfs_bin_cpu1: dvfs-bin@1b {
			reg = <0x1b 0x1>;
			bits = <0 3>;
		};

		dvfs_bin_dsu: dvfs-bin@13{
			reg = <0x13 0x1>;
			bits = <0 3>;
		};
	};

};
